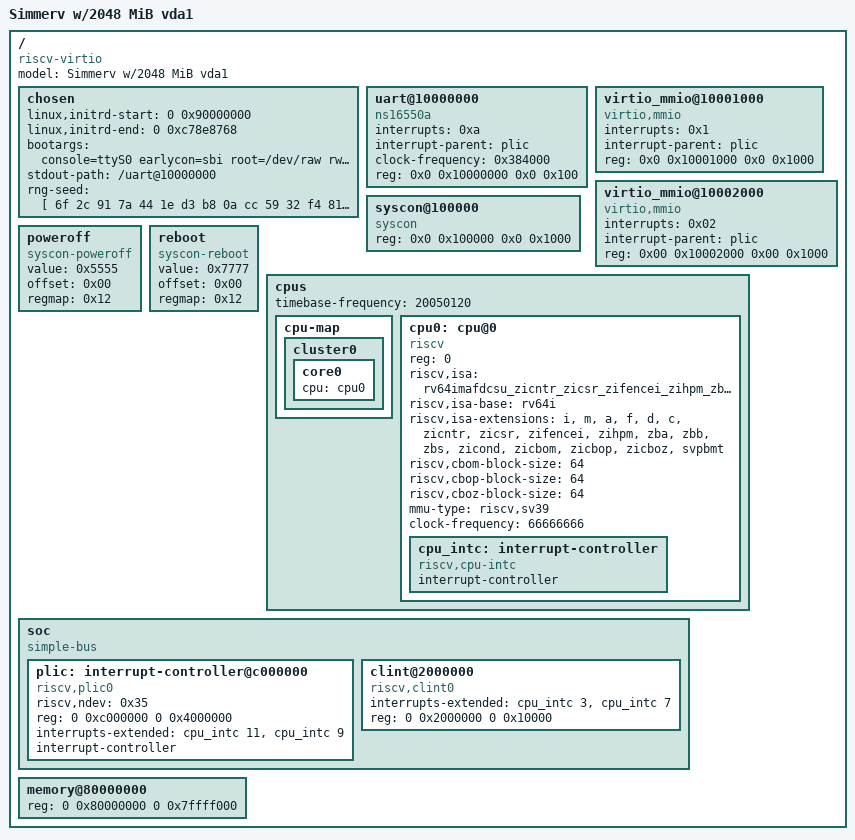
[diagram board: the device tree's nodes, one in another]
/dts-v1/;

/ {
	#address-cells = <2>;
	#size-cells = <2>;
	compatible = "riscv-virtio";
	model = "Simmerv w/2048 MiB vda1";

	chosen {
		linux,initrd-start = <0 0x90000000>;
		linux,initrd-end   = <0 0xc78e8768>; /* exact: ubuntu-mini.cpio (932087656 B, auto-stamped) */
		bootargs = "console=ttyS0 earlycon=sbi root=/dev/raw rw ignore_loglevel random.trust_bootloader=on systemd.log_level=debug systemd.log_target=console";
		stdout-path = "/uart@10000000";

		/* Development-only static seed: replace with per-boot random bytes later. */
		rng-seed = [
			6f 2c 91 7a 44 1e d3 b8
			0a cc 59 32 f4 81 25 9d
			e7 10 ba 6c 38 5f 02 c1
			93 d4 76 af 20 8b ee 41
			15 62 9a cd 57 03 b4 f8
			80 2d 11 6e a9 4c 73 05
			dc 37 f1 98 24 bb 60 0f
			4a e2 7d 36 c5 19 8c a0
		];
	};

        uart@10000000 {
                interrupts = <0xa>;
                interrupt-parent = <&plic>;
                clock-frequency = <0x384000>;
                reg = <0x0 0x10000000 0x0 0x100>;
                compatible = "ns16550a";
        };

        virtio_mmio@10001000 {
                interrupts = <0x1>;
                interrupt-parent = <&plic>;
                reg = <0x0 0x10001000 0x0 0x1000>;
                compatible = "virtio,mmio";
        };

        virtio_mmio@10002000 {
                interrupts = <0x02>;
                interrupt-parent = <&plic>;
                reg = <0x00 0x10002000 0x00 0x1000>;
                compatible = "virtio,mmio";
        };

        syscon@100000 {
                phandle = <0x12>;
                reg = <0x0 0x100000 0x0 0x1000>;
                compatible = "syscon";
        };

        poweroff {
                value = <0x5555>;
                offset = <0x00>;
                regmap = <0x12>;
                compatible = "syscon-poweroff";
        };

        reboot {
                value = <0x7777>;
                offset = <0x00>;
                regmap = <0x12>;
                compatible = "syscon-reboot";
        };

	cpus {
		#address-cells = <1>;
		#size-cells = <0>;
                timebase-frequency = <20050120>; /* 40x LIE (deadline-probe: 90 kernel-s = 3600 real s) (real: ui_clk/5/133 = 501253 Hz). Kernel-seconds run
		                                   at ONE-TENTH real time so systemd's 90s generator deadline becomes
		                                   ~900 real seconds -- the sandboxed generator run outlived the 2x lie's 181s at
		                                   66MHz (measured: EPROTO kill at exactly Hostname+91s, 2 boots).
		                                   Revert to honesty when the core is ~10x faster or the image's
		                                   DefaultTimeoutStartSec is raised. */

		cpu-map {
			cluster0 {
				core0 {
					cpu = <&cpu0>;
				};
			};
		};

		cpu0: cpu@0 {
			device_type = "cpu";
			reg = <0>;
			status = "okay";
			compatible = "riscv";
			riscv,isa = "rv64imafdcsu_zicntr_zicsr_zifencei_zihpm_zba_zbb_zbs_zicond_zicbom_zicbop_zicboz_svpbmt";
			riscv,isa-base = "rv64i";
			riscv,isa-extensions = "i", "m", "a", "f", "d", "c",
				"zicntr", "zicsr", "zifencei", "zihpm",
				"zba", "zbb", "zbs", "zicond",
				"zicbom", "zicbop", "zicboz", "svpbmt";
			riscv,cbom-block-size = <64>;
			riscv,cbop-block-size = <64>;
			riscv,cboz-block-size = <64>;
			mmu-type = "riscv,sv39";
			clock-frequency = <66666666>;

			cpu_intc: interrupt-controller {
				#interrupt-cells = <1>;
				interrupt-controller;
				compatible = "riscv,cpu-intc";
			};
		};
	};

	soc {
		#address-cells = <2>;
		#size-cells = <2>;
		compatible = "simple-bus";
		ranges;

		plic: interrupt-controller@c000000 {
			riscv,ndev = <0x35>;
			reg = <0 0xc000000 0 0x4000000>;
			interrupts-extended = <&cpu_intc 11 &cpu_intc 9>;
			interrupt-controller;
			compatible = "riscv,plic0";
			#interrupt-cells = <1>;
			#address-cells = <0>;
		};

		clint@2000000 {
			interrupts-extended = <&cpu_intc 3 &cpu_intc 7>;
			reg = <0 0x2000000 0 0x10000>;
			compatible = "riscv,clint0";
		};
	};

	memory@80000000 {
		device_type = "memory";
		reg = <0 0x80000000 0 0x7ffff000>; // 2 GiB MiB
	};
};
